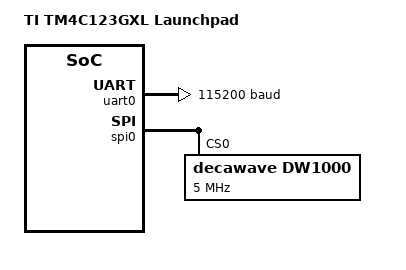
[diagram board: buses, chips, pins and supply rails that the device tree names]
/dts-v1/;

#include <ti/tm4c123.dtsi>

/ {
	model = "TI TM4C123GXL Launchpad";
	compatible = "ti,ti_tm4c123gxl_launchpad","ti,tm4c123gh6pm",
						"ti,tivaware";
	aliases {
		uart-0 = &uart0;
	};

	chosen {
		zephyr,sram = &sram0;
		zephyr,flash = &flash0;
		zephyr,console = &uart0;
	};
};

&uart0 {
	status = "ok";
	current-speed = <115200>;
};

&spi0 {
	status = "ok";
	//cs-gpios = <&gpiod 0 0>;

	dw1000@0 {
		compatible = "decawave,dw1000";
		reg = <0x0>;
		label = "dw1000";
		spi-max-frequency = <5000000>;
		// irq-gpios = <&gpiob 9 0>;
		// reset-gpios = <&gpioa 2 0>;
		// wakeup-gpios = <&gpioa 2 0>;
		status = "ok";
	};
};
